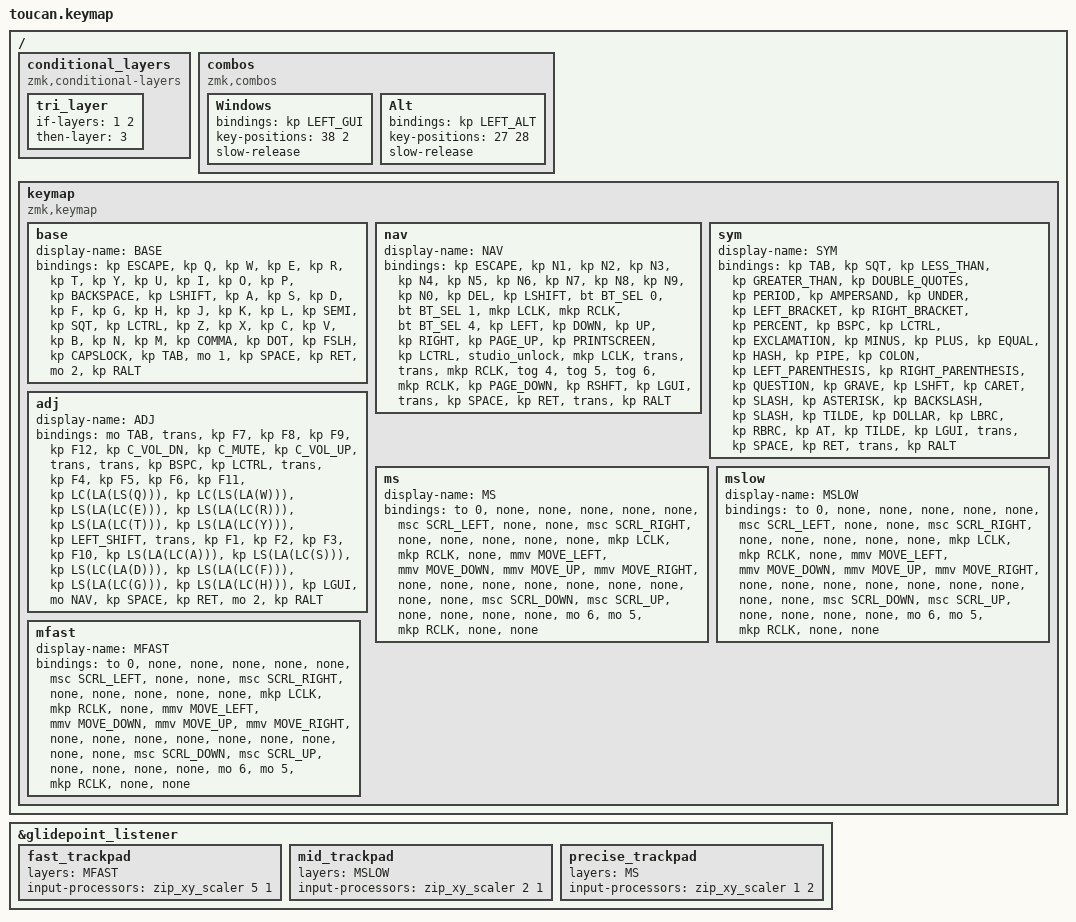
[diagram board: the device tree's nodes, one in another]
#include <behaviors.dtsi>
#include <dt-bindings/zmk/bt.h>
#include <dt-bindings/zmk/keys.h>
#include <dt-bindings/zmk/pointing.h>

#define BASE 0
#define NAV  1
#define SYM  2
#define ADJ  3
#define MS 4
#define MSLOW 5
#define MFAST 6

/ {
    conditional_layers {
        compatible = "zmk,conditional-layers";

        tri_layer {
            if-layers = <1 2>;
            then-layer = <3>;
        };
    };

    combos {
        compatible = "zmk,combos";

        Windows {
            bindings = <&kp LEFT_GUI>;
            key-positions = <38 2>;
            slow-release;
        };

        Alt {
            bindings = <&kp LEFT_ALT>;
            key-positions = <27 28>;
            slow-release;
        };
    };

    keymap {
        compatible = "zmk,keymap";

        base {
            display-name = "BASE";
            bindings = <
&kp ESCAPE  &kp Q  &kp W  &kp E  &kp R  &kp T  &kp Y  &kp U  &kp I  &kp O  &kp P  &kp BACKSPACE  &kp LSHIFT  &kp A  &kp S  &kp D  &kp F  &kp G  &kp H  &kp J  &kp K  &kp L  &kp SEMI  &kp SQT  &kp LCTRL  &kp Z  &kp X  &kp C  &kp V  &kp B  &kp N  &kp M  &kp COMMA  &kp DOT  &kp FSLH  &kp CAPSLOCK  &kp TAB  &mo 1  &kp SPACE  &kp RET  &mo 2  &kp RALT
            >;
        };

        nav {
            display-name = "NAV";
            bindings = <
&kp ESCAPE  &kp N1  &kp N2  &kp N3  &kp N4  &kp N5  &kp N6  &kp N7  &kp N8  &kp N9  &kp N0  &kp DEL  &kp LSHIFT  &bt BT_SEL 0  &bt BT_SEL 1  &mkp LCLK  &mkp RCLK  &bt BT_SEL 4  &kp LEFT  &kp DOWN  &kp UP  &kp RIGHT  &kp PAGE_UP  &kp PRINTSCREEN  &kp LCTRL  &studio_unlock  &mkp LCLK  &trans  &trans  &mkp RCLK  &tog 4  &tog 5  &tog 6  &mkp RCLK  &kp PAGE_DOWN  &kp RSHFT  &kp LGUI  &trans  &kp SPACE  &kp RET  &trans  &kp RALT
            >;
        };

        sym {
            display-name = "SYM";
            bindings = <
&kp TAB  &kp SQT  &kp LESS_THAN  &kp GREATER_THAN  &kp DOUBLE_QUOTES  &kp PERIOD  &kp AMPERSAND  &kp UNDER  &kp LEFT_BRACKET  &kp RIGHT_BRACKET  &kp PERCENT  &kp BSPC  &kp LCTRL  &kp EXCLAMATION  &kp MINUS  &kp PLUS  &kp EQUAL  &kp HASH  &kp PIPE  &kp COLON  &kp LEFT_PARENTHESIS  &kp RIGHT_PARENTHESIS  &kp QUESTION  &kp GRAVE  &kp LSHFT  &kp CARET  &kp SLASH  &kp ASTERISK  &kp BACKSLASH  &kp SLASH  &kp TILDE  &kp DOLLAR  &kp LBRC  &kp RBRC  &kp AT  &kp TILDE  &kp LGUI  &trans  &kp SPACE  &kp RET  &trans  &kp RALT
            >;
        };

        adj {
            display-name = "ADJ";
            bindings = <
&mo TAB  &trans  &kp F7  &kp F8  &kp F9  &kp F12  &kp C_VOL_DN  &kp C_MUTE  &kp C_VOL_UP  &trans  &trans  &kp BSPC  &kp LCTRL  &trans  &kp F4  &kp F5  &kp F6  &kp F11  &kp LC(LA(LS(Q)))  &kp LC(LS(LA(W)))  &kp LS(LA(LC(E)))  &kp LS(LA(LC(R)))  &kp LS(LA(LC(T)))  &kp LS(LA(LC(Y)))  &kp LEFT_SHIFT  &trans  &kp F1  &kp F2  &kp F3  &kp F10  &kp LS(LA(LC(A)))  &kp LS(LA(LC(S)))  &kp LS(LC(LA(D)))  &kp LS(LA(LC(F)))  &kp LS(LA(LC(G)))  &kp LS(LA(LC(H)))  &kp LGUI  &mo NAV  &kp SPACE  &kp RET  &mo 2  &kp RALT
            >;
        };

        ms {
            display-name = "MS";
            bindings = <
&to 0  &none  &none  &none  &none  &none  &msc SCRL_LEFT  &none  &none  &msc SCRL_RIGHT  &none  &none  &none  &none  &none  &mkp LCLK  &mkp RCLK  &none  &mmv MOVE_LEFT  &mmv MOVE_DOWN  &mmv MOVE_UP  &mmv MOVE_RIGHT  &none  &none  &none  &none  &none  &none  &none  &none  &none  &msc SCRL_DOWN  &msc SCRL_UP  &none  &none  &none  &none  &mo 6  &mo 5  &mkp RCLK  &none  &none
            >;
        };

        mslow {
            display-name = "MSLOW";
            bindings = <
&to 0  &none  &none  &none  &none  &none  &msc SCRL_LEFT  &none  &none  &msc SCRL_RIGHT  &none  &none  &none  &none  &none  &mkp LCLK  &mkp RCLK  &none  &mmv MOVE_LEFT  &mmv MOVE_DOWN  &mmv MOVE_UP  &mmv MOVE_RIGHT  &none  &none  &none  &none  &none  &none  &none  &none  &none  &msc SCRL_DOWN  &msc SCRL_UP  &none  &none  &none  &none  &mo 6  &mo 5  &mkp RCLK  &none  &none
            >;
        };

        mfast {
            display-name = "MFAST";
            bindings = <
&to 0  &none  &none  &none  &none  &none  &msc SCRL_LEFT  &none  &none  &msc SCRL_RIGHT  &none  &none  &none  &none  &none  &mkp LCLK  &mkp RCLK  &none  &mmv MOVE_LEFT  &mmv MOVE_DOWN  &mmv MOVE_UP  &mmv MOVE_RIGHT  &none  &none  &none  &none  &none  &none  &none  &none  &none  &msc SCRL_DOWN  &msc SCRL_UP  &none  &none  &none  &none  &mo 6  &mo 5  &mkp RCLK  &none  &none
            >;
        };
    };
};

&glidepoint_listener {
    /*
     * FAST MUST COME FIRST.
     *
     * When MFAST is momentarily held from MS, both layers 4 and 5
     * are active. ZMK uses the first matching input-processor
     * override, not the highest active layer.
     */

    fast_trackpad {
        layers = <MFAST>;
        input-processors = <&zip_xy_scaler 5 1>;
    };

    mid_trackpad {
        layers = <MSLOW>;
        input-processors = <&zip_xy_scaler 2 1>;
    };

    precise_trackpad {
        layers = <MS>;
        input-processors = <&zip_xy_scaler 1 2>;
    };
};
